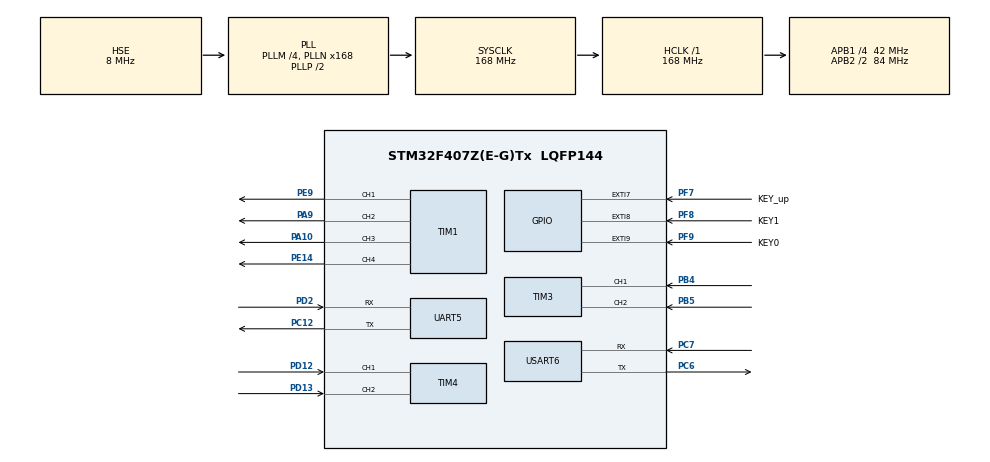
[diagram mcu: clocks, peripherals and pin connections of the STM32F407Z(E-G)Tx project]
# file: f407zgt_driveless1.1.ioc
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Dma.Request0=USART6_RX
Dma.Request1=USART6_TX
Dma.USART6_RX.0.Direction=DMA_PERIPH_TO_MEMORY
Dma.USART6_RX.0.FIFOMode=DMA_FIFOMODE_DISABLE
Dma.USART6_RX.0.Instance=DMA2_Stream1
Dma.USART6_RX.0.MemDataAlignment=DMA_MDATAALIGN_BYTE
Dma.USART6_RX.0.MemInc=DMA_MINC_ENABLE
Dma.USART6_RX.0.Mode=DMA_NORMAL
Dma.USART6_RX.0.PeriphDataAlignment=DMA_PDATAALIGN_BYTE
Dma.USART6_RX.0.PeriphInc=DMA_PINC_DISABLE
Dma.USART6_RX.0.Priority=DMA_PRIORITY_LOW
Dma.USART6_TX.1.Direction=DMA_MEMORY_TO_PERIPH
Dma.USART6_TX.1.FIFOMode=DMA_FIFOMODE_DISABLE
Dma.USART6_TX.1.Instance=DMA2_Stream6
Dma.USART6_TX.1.MemDataAlignment=DMA_MDATAALIGN_BYTE
Dma.USART6_TX.1.MemInc=DMA_MINC_ENABLE
Dma.USART6_TX.1.Mode=DMA_NORMAL
Dma.USART6_TX.1.PeriphDataAlignment=DMA_PDATAALIGN_BYTE
Dma.USART6_TX.1.PeriphInc=DMA_PINC_DISABLE
Dma.USART6_TX.1.Priority=DMA_PRIORITY_LOW
Mcu.Family=STM32F4
Mcu.Name=STM32F407Z(E-G)Tx
Mcu.Package=LQFP144
NVIC.DMA2_Stream1_IRQn=true\:0\:0\:false\:false\:true\:false\:true\:true
NVIC.DMA2_Stream6_IRQn=true\:0\:0\:false\:false\:true\:false\:true\:true
NVIC.EXTI9_5_IRQn=true\:0\:0\:false\:false\:true\:true\:true\:true
NVIC.PriorityGroup=NVIC_PRIORITYGROUP_4
NVIC.TIM2_IRQn=true\:1\:0\:true\:false\:true\:true\:true\:true
NVIC.TIM3_IRQn=true\:0\:0\:false\:false\:true\:true\:true\:true
NVIC.TIM4_IRQn=true\:0\:0\:false\:false\:true\:true\:true\:true
NVIC.USART6_IRQn=true\:0\:0\:false\:false\:true\:true\:true\:true
PA10.Signal=S_TIM1_CH3
PA13.Mode=Serial_Wire
PA13.Signal=SYS_JTMS-SWDIO
PA14.Mode=Serial_Wire
PA14.Signal=SYS_JTCK-SWCLK
PA9.Signal=S_TIM1_CH2
PB4.Signal=S_TIM3_CH1
PB5.Signal=S_TIM3_CH2
PC12.GPIO_PuPd=GPIO_NOPULL
PC12.Mode=Asynchronous
PC12.Signal=UART5_TX
PC6.Mode=Asynchronous
PC6.Signal=USART6_TX
PC7.Mode=Asynchronous
PC7.Signal=USART6_RX
PD12.Signal=S_TIM4_CH1
PD13.Signal=S_TIM4_CH2
PD2.GPIO_PuPd=GPIO_NOPULL
PD2.Mode=Asynchronous
PD2.Signal=UART5_RX
PE14.Signal=S_TIM1_CH4
PE9.Signal=S_TIM1_CH1
PF7.GPIO_Label=KEY_up
PF7.Signal=GPXTI7
PF8.GPIO_Label=KEY1
PF8.Signal=GPXTI8
PF9.GPIO_Label=KEY0
PF9.Signal=GPXTI9
PH0-OSC_IN.Mode=HSE-External-Oscillator
PH0-OSC_IN.Signal=RCC_OSC_IN
PH1-OSC_OUT.Mode=HSE-External-Oscillator
PH1-OSC_OUT.Signal=RCC_OSC_OUT
ProjectManager.HeapSize=0x200
ProjectManager.StackSize=0x400
ProjectManager.TargetToolchain=STM32CubeIDE
RCC.48MHZClocksFreq_Value=84000000
RCC.AHBFreq_Value=168000000
RCC.APB1CLKDivider=RCC_HCLK_DIV4
RCC.APB1Freq_Value=42000000
RCC.APB1TimFreq_Value=84000000
RCC.APB2CLKDivider=RCC_HCLK_DIV2
RCC.APB2Freq_Value=84000000
RCC.APB2TimFreq_Value=168000000
RCC.CortexFreq_Value=168000000
RCC.HCLKFreq_Value=168000000
RCC.HSE_VALUE=8000000
RCC.HSI_VALUE=16000000
RCC.LSE_VALUE=32768
RCC.PLLM=4
RCC.PLLN=168
RCC.PLLSourceVirtual=RCC_PLLSOURCE_HSE
RCC.SYSCLKFreq_VALUE=168000000
RCC.SYSCLKSource=RCC_SYSCLKSOURCE_PLLCLK
RCC.VCOOutputFreq_Value=336000000
SH.S_TIM1_CH1.0=TIM1_CH1,PWM Generation1 CH1
SH.S_TIM1_CH2.0=TIM1_CH2,PWM Generation2 CH2
SH.S_TIM1_CH3.0=TIM1_CH3,PWM Generation3 CH3
SH.S_TIM1_CH4.0=TIM1_CH4,PWM Generation4 CH4
SH.S_TIM3_CH1.0=TIM3_CH1,Encoder_Interface
SH.S_TIM3_CH2.0=TIM3_CH2,Encoder_Interface
SH.S_TIM4_CH1.0=TIM4_CH1,Encoder_Interface
SH.S_TIM4_CH2.0=TIM4_CH2,Encoder_Interface
TIM1.Channel-PWM\ Generation1\ CH1=TIM_CHANNEL_1
TIM1.Channel-PWM\ Generation2\ CH2=TIM_CHANNEL_2
TIM1.Channel-PWM\ Generation3\ CH3=TIM_CHANNEL_3
TIM1.Channel-PWM\ Generation4\ CH4=TIM_CHANNEL_4
TIM1.Period=1000000/10000-1
TIM1.Prescaler=168000000/10000-1
TIM2.Period=100-1
TIM2.Prescaler=16800-1
UART5.VirtualMode=Asynchronous
USART6.VirtualMode=VM_ASYNC
VP_TIM1_VS_ClockSourceINT.Mode=Internal
VP_TIM2_VS_ClockSourceINT.Mode=Internal
board=custom

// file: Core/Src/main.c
/* USER CODE BEGIN Header */
/**
  ******************************************************************************
  * @file           : main.c
  * @brief          : Main program body
  ******************************************************************************
  * @attention
  *
  * Copyright (c) 2023 STMicroelectronics.
  * All rights reserved.
  *
  * This software is licensed under terms that can be found in the LICENSE file
  * in the root directory of this software component.
  * If no LICENSE file comes with this software, it is provided AS-IS.
  *
  ******************************************************************************
  */
/* USER CODE END Header */
#include "main.h"
#include "dma.h"
#include "tim.h"
#include "usart.h"
#include "gpio.h"

/* USER CODE BEGIN Includes */
#include "custom_h/all_header.h"

/* USER CODE END Includes */

void SystemClock_Config(void);

int main(void)
{

  /* MCU Configuration--------------------------------------------------------*/

  /* Reset of all peripherals, Initializes the Flash interface and the Systick. */
  HAL_Init();

  /* Configure the system clock */
  SystemClock_Config();

  /* Initialize all configured peripherals */
  MX_GPIO_Init();
  MX_DMA_Init();
  MX_TIM1_Init();
  MX_TIM2_Init();
  MX_TIM3_Init();
  MX_TIM4_Init();
  MX_USART6_UART_Init();
  MX_UART5_Init();
  /* USER CODE BEGIN 2 */
  Driver_Init.Peripheral_Init();
  /* USER CODE END 2 */

  /* Infinite loop */
  /* USER CODE BEGIN WHILE */
  while (1)
  {
	  Run_Function();
    /* USER CODE END WHILE */

  }
}

void SystemClock_Config(void)
{
  RCC_OscInitTypeDef RCC_OscInitStruct = {0};
  RCC_ClkInitTypeDef RCC_ClkInitStruct = {0};

  /** Configure the main internal regulator output voltage
  */
  __HAL_RCC_PWR_CLK_ENABLE();
  __HAL_PWR_VOLTAGESCALING_CONFIG(PWR_REGULATOR_VOLTAGE_SCALE1);

  /** Initializes the RCC Oscillators according to the specified parameters
  * in the RCC_OscInitTypeDef structure.
  */
  RCC_OscInitStruct.OscillatorType = RCC_OSCILLATORTYPE_HSE;
  RCC_OscInitStruct.HSEState = RCC_HSE_ON;
  RCC_OscInitStruct.PLL.PLLState = RCC_PLL_ON;
  RCC_OscInitStruct.PLL.PLLSource = RCC_PLLSOURCE_HSE;
  RCC_OscInitStruct.PLL.PLLM = 4;
  RCC_OscInitStruct.PLL.PLLN = 168;
  RCC_OscInitStruct.PLL.PLLP = RCC_PLLP_DIV2;
  RCC_OscInitStruct.PLL.PLLQ = 4;
  if (HAL_RCC_OscConfig(&RCC_OscInitStruct) != HAL_OK)
  {
    Error_Handler();
  }

  /** Initializes the CPU, AHB and APB buses clocks
  */
  RCC_ClkInitStruct.ClockType = RCC_CLOCKTYPE_HCLK|RCC_CLOCKTYPE_SYSCLK
                              |RCC_CLOCKTYPE_PCLK1|RCC_CLOCKTYPE_PCLK2;
  RCC_ClkInitStruct.SYSCLKSource = RCC_SYSCLKSOURCE_PLLCLK;
  RCC_ClkInitStruct.AHBCLKDivider = RCC_SYSCLK_DIV1;
  RCC_ClkInitStruct.APB1CLKDivider = RCC_HCLK_DIV4;
  RCC_ClkInitStruct.APB2CLKDivider = RCC_HCLK_DIV2;

  if (HAL_RCC_ClockConfig(&RCC_ClkInitStruct, FLASH_LATENCY_5) != HAL_OK)
  {
    Error_Handler();
  }
}

void Error_Handler(void)
{
  __disable_irq();
  while (1)
  {
  }
}
